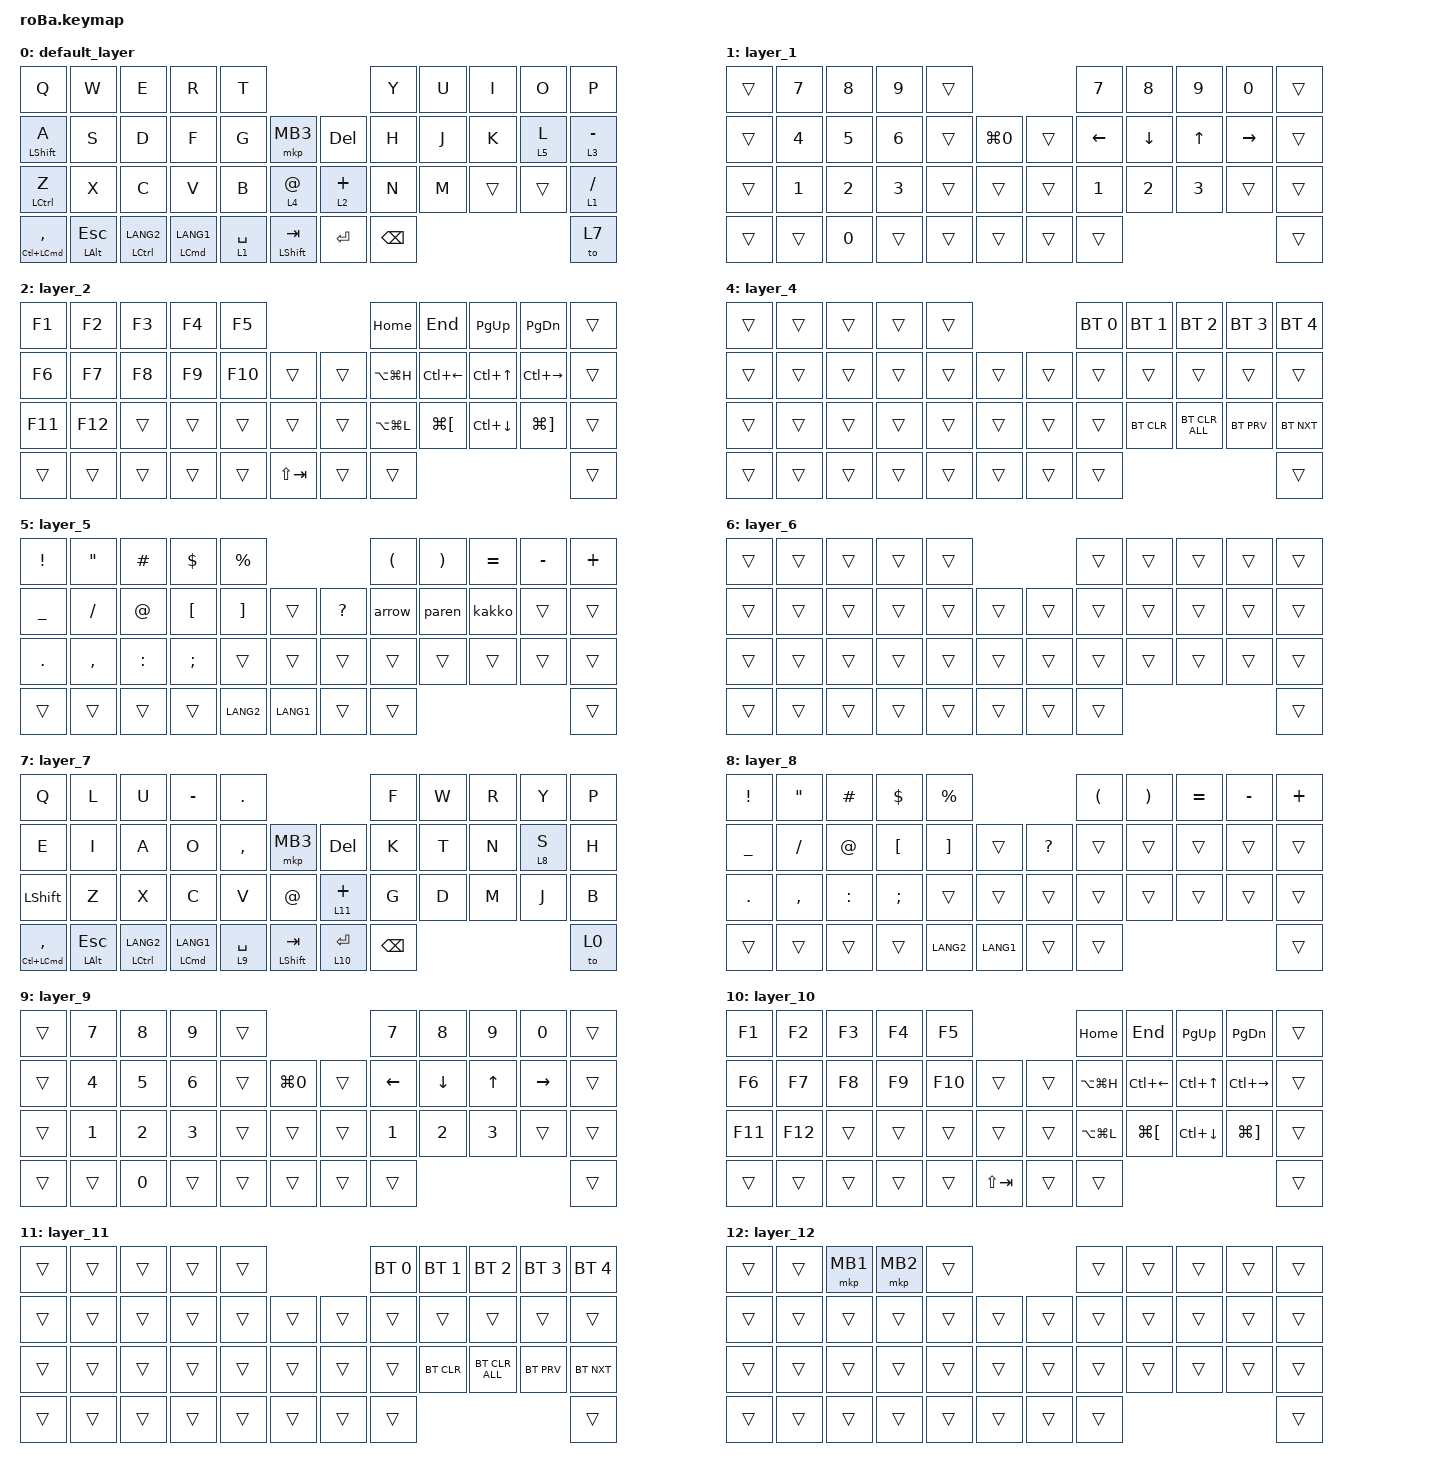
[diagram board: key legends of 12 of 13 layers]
#include <behaviors.dtsi>
#include <dt-bindings/zmk/bt.h>
#include <dt-bindings/zmk/keys.h>
#include <dt-bindings/zmk/pointing.h>

#define ZMK_POINTING_DEFAULT_SCRL_VAL 80

&mt {
    flavor = "balanced";
    quick-tap-ms = <150>;
    tapping-term-ms = <150>;
};

&lt {
    flavor = "balanced";
    quick-tap-ms = <150>;
    tapping-term-ms = <150>;
};

&trackball {
    automouse-layer = <12>;

    scroll-layers = <5>;

    // arrows {
    //     layers = <3>;
    //     bindings =
    //         <&kp RIGHT_ARROW>,
    //         <&kp LEFT_ARROW>,
    //         <&kp UP_ARROW>,
    //         <&kp DOWN_ARROW>;
    //     tick = <10>;
    //     wait-ms = <5>;
    //     tap-ms = <5>;
    // };
};

/ {
    combos {
        compatible = "zmk,combos";

        quote {
            bindings = <&kp SINGLE_QUOTE>;
            key-positions = <5 17>;
        };

        double_quote {
            bindings = <&kp DOUBLE_QUOTES>;
            key-positions = <17 29>;
        };

        semicolon {
            bindings = <&kp SEMICOLON>;
            key-positions = <6 18>;
            timeout-ms = <20>;
        };

        colon {
            bindings = <&kp COLON>;
            key-positions = <18 30>;
        };

        pipe {
            bindings = <&kp PIPE>;
            key-positions = <7 19>;
            timeout-ms = <20>;
        };

        backslash {
            bindings = <&kp BACKSLASH>;
            key-positions = <19 31>;
        };

        tilde {
            bindings = <&kp TILDE>;
            key-positions = <4 14>;
        };

        grave {
            bindings = <&kp GRAVE>;
            key-positions = <14 26>;
        };

        underscore {
            bindings = <&kp UNDERSCORE>;
            key-positions = <3 13>;
        };

        equal {
            bindings = <&kp EQUAL>;
            key-positions = <13 25>;
        };

        lt {
            bindings = <&kp LESS_THAN>;
            key-positions = <2 12>;
        };

        gt {
            bindings = <&kp GREATER_THAN>;
            key-positions = <24 12>;
        };

        exclamation {
            bindings = <&kp EXCLAMATION>;
            key-positions = <1 11>;
        };

        question {
            bindings = <&kp QUESTION>;
            key-positions = <11 23>;
        };

        percent {
            bindings = <&kp PERCENT>;
            key-positions = <1 3>;
        };

        dollar {
            bindings = <&kp DOLLAR>;
            key-positions = <13 11>;
        };

        hash {
            bindings = <&kp HASH>;
            key-positions = <23 25>;
        };

        lpar {
            bindings = <&kp LEFT_PARENTHESIS>;
            key-positions = <12 13>;
        };

        rpar {
            bindings = <&kp RIGHT_PARENTHESIS>;
            key-positions = <18 19>;
        };

        lbkt {
            bindings = <&kp LEFT_BRACKET>;
            key-positions = <3 2>;
            timeout-ms = <20>;
        };

        rbkt {
            bindings = <&kp RIGHT_BRACKET>;
            key-positions = <6 7>;
            timeout-ms = <20>;
        };

        lbrc {
            bindings = <&kp LEFT_BRACE>;
            key-positions = <25 24>;
        };

        rbrc {
            bindings = <&kp RBRC>;
            key-positions = <30 31>;
        };

        caret {
            bindings = <&kp CARET>;
            key-positions = <27 26>;
        };

        amps {
            bindings = <&kp AMPERSAND>;
            key-positions = <0 10>;
            timeout-ms = <20>;
        };

        asterisk {
            bindings = <&kp ASTERISK>;
            key-positions = <10 22>;
        };

        lang1 {
            bindings = <&kp LANG1>;
            key-positions = <38 39>;
        };

        lang2 {
            bindings = <&kp LANG2>;
            key-positions = <40 41>;
        };
    };

    macros {
        to_layer_0: to_layer_0 {
            compatible = "zmk,behavior-macro-one-param";
            #binding-cells = <1>;
            bindings = <&to 0 &macro_param_1to1 &kp MACRO_PLACEHOLDER>;
            label = "TO_LAYER_0";
        };

        arrow: arrow {
            compatible = "zmk,behavior-macro";
            #binding-cells = <0>;
            bindings = <&kp EQUAL &kp GREATER_THAN>;
            label = "ARROW";
        };

        paren: paren {
            compatible = "zmk,behavior-macro";
            #binding-cells = <0>;
            bindings = <&kp LEFT_PARENTHESIS &kp RIGHT_PARENTHESIS &kp LEFT_ARROW>;
            label = "PAREN";
        };

        kakko: kakko {
            compatible = "zmk,behavior-macro";
            #binding-cells = <0>;
            bindings = <&kp LEFT_BRACKET &kp RIGHT_BRACKET &kp LEFT_ARROW>;
            label = "KAKKO";
        };
    };

    behaviors {
        lt_hold: lt_hold {
            compatible = "zmk,behavior-hold-tap";
            label = "LT_HOLD";
            flavor = "hold-preferred";
            quick-tap-ms = <150>;
            tapping-term-ms = <150>;
            bindings = <&mo>, <&kp>;

            #binding-cells = <2>;
        };

        lt_to_layer_0: lt_to_layer_0 {
            compatible = "zmk,behavior-hold-tap";
            label = "LAYER_TAP_TO_0";
            bindings = <&mo>, <&to_layer_0>;

            #binding-cells = <2>;
            tapping-term-ms = <200>;
        };

        encoder_msc_down_up: encoder_msc_down_up {
            compatible = "zmk,behavior-sensor-rotate";
            label = "ENCODER_MSC_DOWN_UP";
            #sensor-binding-cells = <0>;
            bindings = <&msc SCRL_DOWN>, <&msc SCRL_UP>;

            tap-ms = <20>;
        };
    };

    keymap {
        compatible = "zmk,keymap";

        default_layer {
            bindings = <
&kp Q                       &kp W             &kp E            &kp R                   &kp T                                                    &kp Y        &kp U  &kp I     &kp O     &kp P
&mt LSHIFT A                 &kp S             &kp D            &kp F                   &kp G             &mkp MB3                &kp DELETE     &kp H        &kp J  &kp K     &lt 5 L   &lt 3 MINUS
&mt LCTRL Z                 &kp X             &kp C            &kp V                   &kp B             &lt 4 AT_SIGN           &lt 2 PLUS     &kp N        &kp M  &trans    &trans    &lt 1 SLASH
&mt LC(LEFT_COMMAND) COMMA  &mt LEFT_ALT ESC  &mt LCTRL LANG2  &mt LEFT_COMMAND LANG1  &lt_hold 1 SPACE  &mt LEFT_SHIFT TAB      &kp ENTER    &kp BACKSPACE                             &to 7
            >;

            sensor-bindings = <&encoder_msc_down_up>;
        };

        layer_1 {
            bindings = <
&trans  &kp NUMBER_7  &kp NUMBER_8  &kp NUMBER_9  &trans                                &kp NUMBER_7    &kp NUMBER_8    &kp NUMBER_9    &kp NUMBER_0    &trans
&trans  &kp NUMBER_4  &kp NUMBER_5  &kp NUMBER_6  &trans  &kp LG(NUMBER_0)      &trans  &kp LEFT_ARROW  &kp DOWN_ARROW  &kp UP_ARROW    &kp RIGHT_ARROW &trans
&trans  &kp NUMBER_1  &kp NUMBER_2  &kp NUMBER_3  &trans  &trans                &trans  &kp NUMBER_1    &kp NUMBER_2    &kp NUMBER_3    &trans          &trans
&trans  &trans        &kp N0        &trans        &trans  &trans                &trans  &trans                                                          &trans
            >;

            sensor-bindings = <&inc_dec_kp LG(MINUS) LG(PLUS)>;
        };

        layer_2 {
            bindings = <
&kp F1   &kp F2   &kp F3  &kp F4  &kp F5                            &kp HOME       &kp END               &kp PAGE_UP         &kp PAGE_DOWN          &trans
&kp F6   &kp F7   &kp F8  &kp F9  &kp F10  &trans           &trans  &kp LA(LG(H))  &kp LC(LEFT_ARROW)    &kp LC(UP_ARROW)    &kp LC(RIGHT_ARROW)    &trans
&kp F11  &kp F12  &trans  &trans  &trans   &trans           &trans  &kp LA(LG(L))  &kp LG(LEFT_BRACKET)  &kp LC(DOWN_ARROW)  &kp LG(RIGHT_BRACKET)  &trans
&trans   &trans   &trans  &trans  &trans   &kp LS(TAB)      &trans  &trans                                                                          &trans
            >;

            sensor-bindings = <&inc_dec_kp C_VOL_DN C_VOL_UP>;
        };

        layer_3 {
            bindings = <
&kp LC(LA(LG(Q)))  &kp LA(LC(LG(W)))  &kp LA(LC(LG(E)))  &kp LA(LC(LG(R)))  &kp LA(LC(LG(T)))                      &trans  &trans           &trans       &kp LS(LA(F))             &trans
&kp LA(LC(LG(A)))  &kp LA(LC(LG(S)))  &kp LA(LC(LG(D)))  &kp LA(LC(LG(F)))  &kp LA(LC(LG(G)))  &trans      &trans  &trans  &kp LS(LC(TAB))  &kp LC(TAB)  &kp LS(LC(LG(NUMBER_4)))  &trans
&kp LA(LC(LG(Z)))  &kp LA(LC(LG(X)))  &kp LA(LC(LG(C)))  &kp LA(LC(LG(V)))  &kp LA(LC(LG(B)))  &trans      &trans  &trans  &trans           &kp LG(W)    &trans                    &trans
&trans             &trans             &trans             &trans             &trans             &trans      &trans  &trans                                                          &trans
            >;

            sensor-bindings = <&inc_dec_kp LC(LS(TAB)) LC(TAB)>;
        };

        layer_4 {
            bindings = <
&trans  &trans  &trans  &trans  &trans                      &bt BT_SEL 0  &bt BT_SEL 1  &bt BT_SEL 2    &bt BT_SEL 3  &bt BT_SEL 4
&trans  &trans  &trans  &trans  &trans  &trans      &trans  &trans        &trans        &trans          &trans        &trans
&trans  &trans  &trans  &trans  &trans  &trans      &trans  &trans        &bt BT_CLR    &bt BT_CLR_ALL  &bt BT_PRV    &bt BT_NXT
&trans  &trans  &trans  &trans  &trans  &trans      &trans  &trans                                                    &trans
            >;
        };

        layer_5 {
            bindings = <
&kp EXCLAMATION  &kp DOUBLE_QUOTES  &kp HASH   &kp DLLR          &kp PERCENT                                  &kp LEFT_PARENTHESIS  &kp RIGHT_PARENTHESIS  &kp EQUAL  &kp MINUS  &kp PLUS
&kp UNDERSCORE   &kp SLASH          &kp AT     &kp LEFT_BRACKET  &kp RIGHT_BRACKET  &trans      &kp QUESTION  &arrow                &paren                 &kakko     &trans     &trans
&kp PERIOD       &kp COMMA          &kp COLON  &kp SEMICOLON     &trans             &trans      &trans        &trans                &trans                 &trans     &trans     &trans
&trans           &trans             &trans     &trans            &kp LANG2          &kp LANG1   &trans        &trans                                                             &trans
            >;
        };

        layer_6 {
            bindings = <
&trans  &trans  &trans  &trans  &trans                      &trans  &trans  &trans  &trans  &trans
&trans  &trans  &trans  &trans  &trans  &trans      &trans  &trans  &trans  &trans  &trans  &trans
&trans  &trans  &trans  &trans  &trans  &trans      &trans  &trans  &trans  &trans  &trans  &trans
&trans  &trans  &trans  &trans  &trans  &trans      &trans  &trans                          &trans
            >;
        };


        layer_7 {
            bindings = <
&kp Q                       &kp L             &kp U            &kp MINUS               &kp DOT                                                        &kp F        &kp W  &kp R     &kp Y     &kp P
&kp E                       &kp I             &kp A            &kp O                   &kp COMMA         &mkp MB3                &kp DELETE     &kp K        &kp T  &kp N     &lt 8 S   &kp H
&kp LSHIFT                  &kp Z             &kp X            &kp C                   &kp V             &kp AT_SIGN             &lt 11 PLUS    &kp G        &kp D  &kp M     &kp J     &kp B
&mt LC(LEFT_COMMAND) COMMA  &mt LEFT_ALT ESC  &mt LCTRL LANG2  &mt LEFT_COMMAND LANG1  &lt_hold 9 SPACE  &mt LEFT_SHIFT TAB      &lt 10 ENTER  &kp BACKSPACE                             &to 0
            >;

            sensor-bindings = <&encoder_msc_down_up>;
        };

        layer_8 {
            bindings = <
&kp EXCLAMATION  &kp DOUBLE_QUOTES  &kp HASH   &kp DLLR          &kp PERCENT                                  &kp LEFT_PARENTHESIS  &kp RIGHT_PARENTHESIS  &kp EQUAL  &kp MINUS  &kp PLUS
&kp UNDERSCORE   &kp SLASH          &kp AT     &kp LEFT_BRACKET  &kp RIGHT_BRACKET  &trans      &kp QUESTION  &trans                &trans                 &trans     &trans     &trans
&kp PERIOD       &kp COMMA          &kp COLON  &kp SEMICOLON     &trans             &trans      &trans        &trans                &trans                 &trans     &trans     &trans
&trans           &trans             &trans     &trans            &kp LANG2          &kp LANG1   &trans        &trans                                                             &trans
            >;
        };

        layer_9 {
            bindings = <
&trans  &kp NUMBER_7  &kp NUMBER_8  &kp NUMBER_9  &trans                                &kp NUMBER_7    &kp NUMBER_8    &kp NUMBER_9    &kp NUMBER_0    &trans
&trans  &kp NUMBER_4  &kp NUMBER_5  &kp NUMBER_6  &trans  &kp LG(NUMBER_0)      &trans  &kp LEFT_ARROW  &kp DOWN_ARROW  &kp UP_ARROW    &kp RIGHT_ARROW &trans
&trans  &kp NUMBER_1  &kp NUMBER_2  &kp NUMBER_3  &trans  &trans                &trans  &kp NUMBER_1    &kp NUMBER_2    &kp NUMBER_3    &trans          &trans
&trans  &trans        &kp N0        &trans        &trans  &trans                &trans  &trans                                                          &trans
            >;

            sensor-bindings = <&inc_dec_kp LG(MINUS) LG(PLUS)>;
        };

        layer_10 {
            bindings = <
&kp F1   &kp F2   &kp F3  &kp F4  &kp F5                            &kp HOME       &kp END               &kp PAGE_UP         &kp PAGE_DOWN          &trans
&kp F6   &kp F7   &kp F8  &kp F9  &kp F10  &trans           &trans  &kp LA(LG(H))  &kp LC(LEFT_ARROW)    &kp LC(UP_ARROW)    &kp LC(RIGHT_ARROW)    &trans
&kp F11  &kp F12  &trans  &trans  &trans   &trans           &trans  &kp LA(LG(L))  &kp LG(LEFT_BRACKET)  &kp LC(DOWN_ARROW)  &kp LG(RIGHT_BRACKET)  &trans
&trans   &trans   &trans  &trans  &trans   &kp LS(TAB)      &trans  &trans                                                                          &trans
            >;

            sensor-bindings = <&inc_dec_kp C_VOL_DN C_VOL_UP>;
        };

        layer_11 {
            bindings = <
&trans  &trans  &trans  &trans  &trans                      &bt BT_SEL 0  &bt BT_SEL 1  &bt BT_SEL 2    &bt BT_SEL 3  &bt BT_SEL 4
&trans  &trans  &trans  &trans  &trans  &trans      &trans  &trans        &trans        &trans          &trans        &trans
&trans  &trans  &trans  &trans  &trans  &trans      &trans  &trans        &bt BT_CLR    &bt BT_CLR_ALL  &bt BT_PRV    &bt BT_NXT
&trans  &trans  &trans  &trans  &trans  &trans      &trans  &trans                                                    &trans
            >;
        };

        layer_12 {
            bindings = <
&trans  &trans  &mkp MB1  &mkp MB2  &trans                      &trans  &trans  &trans  &trans  &trans
&trans  &trans  &trans    &trans    &trans  &trans      &trans  &trans  &trans  &trans  &trans  &trans
&trans  &trans  &trans    &trans    &trans  &trans      &trans  &trans  &trans  &trans  &trans  &trans
&trans  &trans  &trans    &trans    &trans  &trans      &trans  &trans                          &trans
            >;
        };
    };
};
